AUTOSAR XML (schema 00049)
package /Application/DltConfig
  dlt log channel to process mapping DltLogChannelToProcessMapping_IntelligentWiper_TO_IntelligentWiper: dlt-log-channel=IntelligentWiper, process=IntelligentWiper
package /Application/Executable
  executable IntelligentWiper: category=APPLICATION_LEVEL, logging-behavior=USES-LOGGING, reporting-behavior=REPORTS-EXECUTION-STATE, version=1.0.0
    root sw component prototype AA: application-type=IntelligentWiper
package /Application/Manifest
  6 x service instance to port prototype mapping:
    IntelligentWiper_AA_RPort_BCM_WiperWash: port-prototype=AA.RPort_BCM_WiperWash, service-instance=EEVP_IntelligentWiper_Consumer_BCM_WiperWash
    IntelligentWiper_AA_RPort_Snsr_USS: port-prototype=AA.RPort_Snsr_USS, service-instance=EEVP_IntelligentWiper_Consumer_Snsr_USS
    IntelligentWiper_AA_RPort_VCS_AccrPedal: port-prototype=AA.RPort_VCS_AccrPedal, service-instance=EEVP_IntelligentWiper_Consumer_VCS_AccrPedal
    IntelligentWiper_AA_RPort_VCS_BrakePedal: port-prototype=AA.RPort_VCS_BrakePedal, service-instance=EEVP_IntelligentWiper_Consumer_VCS_BrakePedal
    IntelligentWiper_AA_RPort_VCS_Gear: port-prototype=AA.RPort_VCS_Gear, service-instance=EEVP_IntelligentWiper_Consumer_VCS_Gear
    IntelligentWiper_AA_RPort_VCS_VehSpd: port-prototype=AA.RPort_VCS_VehSpd, service-instance=EEVP_IntelligentWiper_Consumer_VCS_VehSpd
package /Application/Process
  process IntelligentWiper: executable=IntelligentWiper, state-dependent-startup-config{execution-dependency=CM.Running, function-group-state=MachineFG.Startup, resource-group=DefaultResourceGroup, startup-config=IntelligentWiper}
    process state machine IntelligentWiper: type=ProcessState
package /Application/StartupConfig
  startup config set EEVP_IntelligentWiper_StartupConfig
    startup config IntelligentWiper: scheduling-policy=SCHED_OTHER, scheduling-priority=0
package /Application/SwComponent
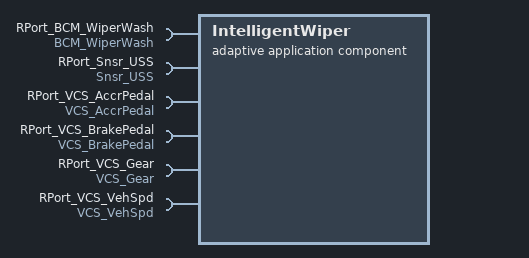
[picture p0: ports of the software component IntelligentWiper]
  adaptive application sw component type IntelligentWiper
    6 x require port:
      RPort_BCM_WiperWash: required-interface=BCM_WiperWash
      RPort_Snsr_USS: required-interface=Snsr_USS
      RPort_VCS_AccrPedal: required-interface=VCS_AccrPedal
      RPort_VCS_BrakePedal: required-interface=VCS_BrakePedal
      RPort_VCS_Gear: required-interface=VCS_Gear
      RPort_VCS_VehSpd: required-interface=VCS_VehSpd
